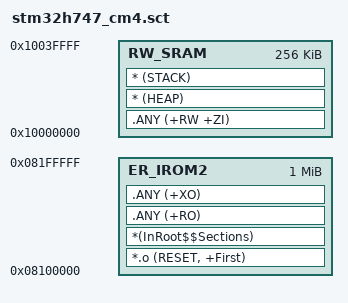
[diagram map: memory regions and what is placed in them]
; *************************************************************
; *** Scatter-Loading Description File generated by uVision ***
; *************************************************************

LR_IROM2 0x08100000 0x00100000  {      ; load region size_region
  ER_IROM2 0x08100000 0x00100000  {    ; load address = execution address
   *.o (RESET, +First)
   *(InRoot$$Sections)
   .ANY (+RO)
   .ANY (+XO)
  }

  RW_SRAM 0x10000000 0x00040000  {     ; SRAM1 + SRAM2
   .ANY (+RW +ZI)                      ; RW data
   * (HEAP)                            ; Heap
   * (STACK)                           ; Stack
  }
}

